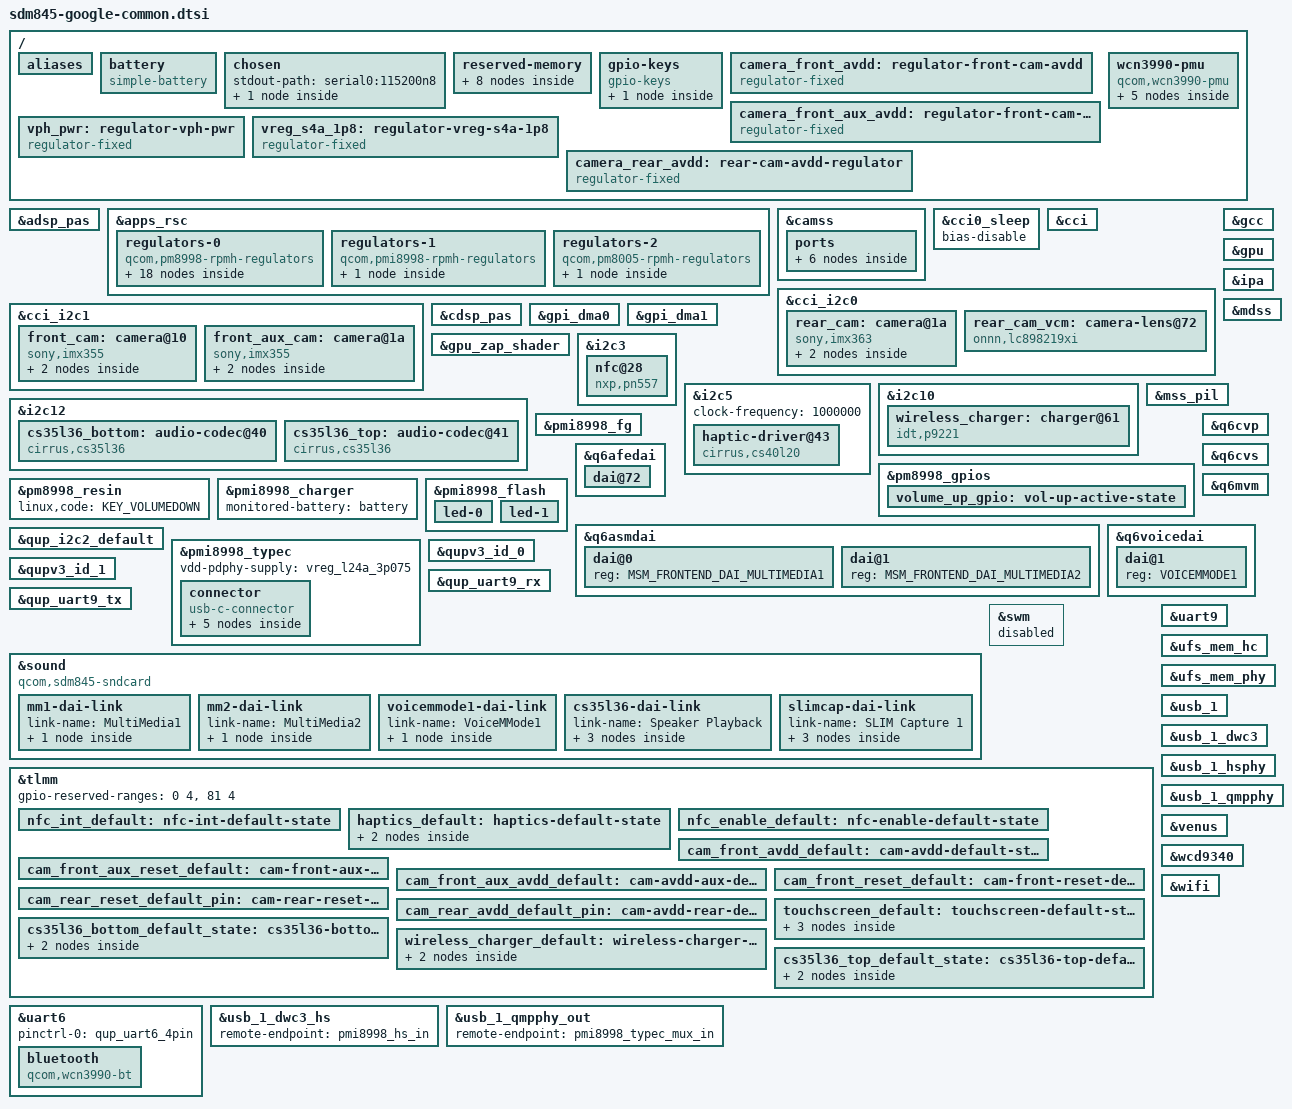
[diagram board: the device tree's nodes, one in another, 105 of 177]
// SPDX-License-Identifier: GPL-2.0-only

/dts-v1/;

#include <dt-bindings/arm/qcom,ids.h>
#include <dt-bindings/dma/qcom-gpi.h>
#include <dt-bindings/input/linux-event-codes.h>
#include <dt-bindings/interrupt-controller/irq.h>
#include <dt-bindings/leds/common.h>
#include <dt-bindings/media/video-interface-devices.h>
#include <dt-bindings/media/video-interfaces.h>
#include <dt-bindings/regulator/qcom,rpmh-regulator.h>
#include <dt-bindings/sound/qcom,q6afe.h>
#include <dt-bindings/sound/qcom,q6asm.h>
#include <dt-bindings/sound/qcom,q6voice.h>
#include <dt-bindings/sound/qcom,wcd934x.h>
#include <dt-bindings/usb/pd.h>

#include "sdm845.dtsi"
#include "sdm845-wcd9340.dtsi"
#include "pm8998.dtsi"
#include "pmi8998.dtsi"

/delete-node/ &mpss_region;
/delete-node/ &venus_mem;
/delete-node/ &cdsp_mem;
/delete-node/ &mba_region;
/delete-node/ &slpi_mem;
/delete-node/ &spss_mem;
/delete-node/ &rmtfs_mem;

/ {
	chassis-type = "handset";
	qcom,board-id = <0x00021505 0>;
	qcom,msm-id = <QCOM_ID_SDM845 0x20001>;

	aliases {
		serial0 = &uart9;
		serial1 = &uart6;
	};

	battery: battery {
		compatible = "simple-battery";
	};

	chosen {
		#address-cells = <2>;
		#size-cells = <2>;
		ranges;

		stdout-path = "serial0:115200n8";

		/* Use display framebuffer as setup by bootloader */
		framebuffer0: framebuffer-0 {
			compatible = "simple-framebuffer";
			memory-region = <&cont_splash_mem>;

			format = "a8r8g8b8";
		};
	};

	reserved-memory {
		cont_splash_mem: splash@9d400000 {
			reg = <0 0x9d400000 0 0x02400000>;
			no-map;
		};

		mpss_region: memory@8e000000 {
			reg = <0 0x8e000000 0 0x9800000>;
			no-map;
		};

		venus_mem: venus@97800000 {
			reg = <0 0x97800000 0 0x500000>;
			no-map;
		};

		cdsp_mem: cdsp-mem@97d00000 {
			reg = <0 0x97d00000 0 0x800000>;
			no-map;
		};

		mba_region: mba@98500000 {
			reg = <0 0x98500000 0 0x200000>;
			no-map;
		};

		slpi_mem: slpi@98700000 {
			reg = <0 0x98700000 0 0x1400000>;
			no-map;
		};

		spss_mem: spss@99b00000 {
			reg = <0 0x99b00000 0 0x100000>;
			no-map;
		};

		rmtfs_mem: rmtfs-region@f2700000 {
			compatible = "qcom,rmtfs-mem";
			reg = <0 0xf2700000 0 0x202000>;
			qcom,use-guard-pages;
			no-map;

			qcom,client-id = <1>;
			qcom,vmid = <QCOM_SCM_VMID_MSS_MSA>;
		};
	};

	gpio-keys {
		compatible = "gpio-keys";
		label = "Volume keys";
		autorepeat;

		pinctrl-0 = <&volume_up_gpio>;
		pinctrl-names = "default";

		key-vol-up {
			label = "Volume Up";
			linux,code = <KEY_VOLUMEUP>;
			gpios = <&pm8998_gpios 6 GPIO_ACTIVE_LOW>;
			debounce-interval = <15>;
		};
	};

	camera_front_avdd: regulator-front-cam-avdd {
		compatible = "regulator-fixed";
		regulator-name = "front_cam_avdd";

		regulator-min-microvolt = <2800000>;
		regulator-max-microvolt = <2800000>;

		gpios = <&tlmm 8 GPIO_ACTIVE_HIGH>;
		enable-active-high;

		pinctrl-0 = <&cam_front_avdd_default>;
		pinctrl-names = "default";

		vin-supply = <&vreg_bob>;
	};

	camera_front_aux_avdd: regulator-front-cam-aux-avdd {
		compatible = "regulator-fixed";
		regulator-name = "front_cam_aux_avdd";

		regulator-min-microvolt = <2800000>;
		regulator-max-microvolt = <2800000>;

		gpios = <&tlmm 14 GPIO_ACTIVE_HIGH>;
		enable-active-high;

		pinctrl-0 = <&cam_front_aux_avdd_default>;
		pinctrl-names = "default";

		vin-supply = <&vreg_bob>;
	};

	vph_pwr: regulator-vph-pwr {
		compatible = "regulator-fixed";
		regulator-name = "vph_pwr";
		regulator-min-microvolt = <3700000>;
		regulator-max-microvolt = <3700000>;
	};

	vreg_s4a_1p8: regulator-vreg-s4a-1p8 {
		compatible = "regulator-fixed";
		regulator-name = "vreg_s4a_1p8";

		regulator-min-microvolt = <1800000>;
		regulator-max-microvolt = <1800000>;
		regulator-always-on;
		regulator-boot-on;

		vin-supply = <&vph_pwr>;
	};

	/*
	 * CAM_VANA0 in the downstream overlay's cam-sensor@0: a GPIO switch off
	 * the BOB rail, same shape as the two front sensors' avdd above.
	 */
	camera_rear_avdd: rear-cam-avdd-regulator {
		compatible = "regulator-fixed";
		regulator-name = "rear_cam_avdd";

		regulator-min-microvolt = <2800000>;
		regulator-max-microvolt = <2800000>;

		gpios = <&tlmm 16 GPIO_ACTIVE_HIGH>;
		enable-active-high;

		pinctrl-0 = <&cam_rear_avdd_default_pin>;
		pinctrl-names = "default";

		vin-supply = <&vreg_bob>;
	};

	wcn3990-pmu {
		compatible = "qcom,wcn3990-pmu";

		vddio-supply = <&vreg_s4a_1p8>;
		vddxo-supply = <&vreg_l7a_1p8>;
		vddrf-supply = <&vreg_l17a_1p3>;
		vddch0-supply = <&vreg_l25a_3p3>;

		regulators {
			vreg_pmu_io: ldo0 {
				regulator-name = "vreg_pmu_io";
			};

			vreg_pmu_xo: ldo1 {
				regulator-name = "vreg_pmu_xo";
			};

			vreg_pmu_rf: ldo2 {
				regulator-name = "vreg_pmu_rf";
			};

			vreg_pmu_ch0: ldo3 {
				regulator-name = "vreg_pmu_ch0";
			};
		};
	};
};

&adsp_pas {
	firmware-name = "qcom/sdm845/Google/blueline/adsp.mbn";

	status = "okay";
};

&apps_rsc {
	regulators-0 {
		compatible = "qcom,pm8998-rpmh-regulators";
		qcom,pmic-id = "a";

		vdd-s1-supply = <&vph_pwr>;
		vdd-s2-supply = <&vph_pwr>;
		vdd-s3-supply = <&vph_pwr>;
		vdd-s4-supply = <&vph_pwr>;
		vdd-s5-supply = <&vph_pwr>;
		vdd-s6-supply = <&vph_pwr>;
		vdd-s7-supply = <&vph_pwr>;
		vdd-s8-supply = <&vph_pwr>;
		vdd-s9-supply = <&vph_pwr>;
		vdd-s10-supply = <&vph_pwr>;
		vdd-s11-supply = <&vph_pwr>;
		vdd-s12-supply = <&vph_pwr>;
		vdd-s13-supply = <&vph_pwr>;
		vdd-l1-l27-supply = <&vreg_s7a_1p025>;
		vdd-l2-l8-l17-supply = <&vreg_s3a_1p35>;
		vdd-l3-l11-supply = <&vreg_s7a_1p025>;
		vdd-l4-l5-supply = <&vreg_s7a_1p025>;
		vdd-l6-supply = <&vph_pwr>;
		vdd-l7-l12-l14-l15-supply = <&vreg_s5a_2p04>;
		vdd-l9-supply = <&vreg_bob>;
		vdd-l10-l23-l25-supply = <&vreg_bob>;
		vdd-l13-l19-l21-supply = <&vreg_bob>;
		vdd-l16-l28-supply = <&vreg_bob>;
		vdd-l18-l22-supply = <&vreg_bob>;
		vdd-l20-l24-supply = <&vreg_bob>;
		vdd-l26-supply = <&vreg_s3a_1p35>;
		vin-lvs-1-2-supply = <&vreg_s4a_1p8>;

		vreg_s3a_1p35: smps3 {
			regulator-min-microvolt = <1352000>;
			regulator-max-microvolt = <1352000>;
		};

		vreg_s5a_2p04: smps5 {
			regulator-min-microvolt = <1904000>;
			regulator-max-microvolt = <2040000>;
		};

		vreg_s7a_1p025: smps7 {
			regulator-min-microvolt = <900000>;
			regulator-max-microvolt = <1028000>;
		};

		vdda_mipi_dsi0_pll:
		vreg_l1a_0p875: ldo1 {
			regulator-min-microvolt = <880000>;
			regulator-max-microvolt = <880000>;
			regulator-initial-mode = <RPMH_REGULATOR_MODE_HPM>;
			regulator-boot-on;
		};

		vreg_l5a_0p8: ldo5 {
			regulator-min-microvolt = <800000>;
			regulator-max-microvolt = <800000>;
			regulator-initial-mode = <RPMH_REGULATOR_MODE_HPM>;
		};

		vreg_l12a_1p8: ldo12 {
			regulator-min-microvolt = <1800000>;
			regulator-max-microvolt = <1800000>;
			regulator-initial-mode = <RPMH_REGULATOR_MODE_HPM>;
		};

		vreg_l7a_1p8: ldo7 {
			regulator-min-microvolt = <1800000>;
			regulator-max-microvolt = <1800000>;
			regulator-initial-mode = <RPMH_REGULATOR_MODE_HPM>;
		};

		vreg_l13a_2p95: ldo13 {
			regulator-min-microvolt = <1800000>;
			regulator-max-microvolt = <2960000>;
			regulator-initial-mode = <RPMH_REGULATOR_MODE_HPM>;
		};

		vreg_l14a_1p8: ldo14 {
			regulator-min-microvolt = <1800000>;
			regulator-max-microvolt = <1800000>;
			regulator-initial-mode = <RPMH_REGULATOR_MODE_HPM>;
			regulator-boot-on;
			/*
			 * We can't properly bring the panel back if it gets turned off
			 * so keep it's regulators always on for now.
			 */
			regulator-always-on;
		};

		vreg_l17a_1p3: ldo17 {
			regulator-min-microvolt = <1304000>;
			regulator-max-microvolt = <1304000>;
			regulator-initial-mode = <RPMH_REGULATOR_MODE_HPM>;
		};

		vreg_l19a_3p3: ldo19 {
			regulator-min-microvolt = <3300000>;
			regulator-max-microvolt = <3312000>;
			regulator-initial-mode = <RPMH_REGULATOR_MODE_HPM>;
			/*
			 * The touchscreen needs this to be 3.3v, which is apparently
			 * quite close to the hardware limit for this LDO (3.312v)
			 * It must be kept in high power mode to prevent TS brownouts
			 */
			regulator-allowed-modes = <RPMH_REGULATOR_MODE_HPM>;
		};

		vreg_l20a_2p95: ldo20 {
			regulator-min-microvolt = <2960000>;
			regulator-max-microvolt = <2968000>;
			regulator-initial-mode = <RPMH_REGULATOR_MODE_HPM>;
		};

		vreg_l21a_2p95: ldo21 {
			regulator-min-microvolt = <2960000>;
			regulator-max-microvolt = <2968000>;
			regulator-initial-mode = <RPMH_REGULATOR_MODE_HPM>;
		};

		vreg_l24a_3p075: ldo24 {
			regulator-min-microvolt = <3088000>;
			regulator-max-microvolt = <3088000>;
			regulator-initial-mode = <RPMH_REGULATOR_MODE_HPM>;
		};

		vreg_l25a_3p3: ldo25 {
			regulator-min-microvolt = <3300000>;
			regulator-max-microvolt = <3312000>;
			regulator-initial-mode = <RPMH_REGULATOR_MODE_HPM>;
		};

		vdda_mipi_dsi0_1p2:
		vreg_l26a_1p2: ldo26 {
			regulator-min-microvolt = <1200000>;
			regulator-max-microvolt = <1200000>;
			regulator-initial-mode = <RPMH_REGULATOR_MODE_HPM>;
			regulator-boot-on;
		};

		vreg_l28a_3p0: ldo28 {
			regulator-min-microvolt = <2856000>;
			regulator-max-microvolt = <3008000>;
			regulator-initial-mode = <RPMH_REGULATOR_MODE_LPM>;
			regulator-boot-on;
			/*
			 * We can't properly bring the panel back if it gets turned off
			 * so keep it's regulators always on for now.
			 */
			regulator-always-on;
		};

		vreg_lvs1_1p8: lvs1 {
			regulator-min-microvolt = <1800000>;
			regulator-max-microvolt = <1800000>;
			/*
			 * Camera I/O rail. The IMX363 and the VD6281 colour sensor
			 * share CCI0 with the VCM and clamp the bus when this rail
			 * is off, so keep it on until the bus users are sequenced.
			 */
			regulator-always-on;
		};
	};

	regulators-1 {
		compatible = "qcom,pmi8998-rpmh-regulators";
		qcom,pmic-id = "b";

		vdd-bob-supply = <&vph_pwr>;

		vreg_bob: bob {
			regulator-min-microvolt = <3312000>;
			regulator-max-microvolt = <3600000>;
			regulator-initial-mode = <RPMH_REGULATOR_MODE_AUTO>;
			regulator-allow-bypass;
		};
	};

	regulators-2 {
		compatible = "qcom,pm8005-rpmh-regulators";
		qcom,pmic-id = "c";

		vdd-s1-supply = <&vph_pwr>;
		vdd-s2-supply = <&vph_pwr>;
		vdd-s3-supply = <&vph_pwr>;
		vdd-s4-supply = <&vph_pwr>;

		vreg_s3c_0p6: smps3 {
			regulator-min-microvolt = <600000>;
			regulator-max-microvolt = <600000>;
		};
	};
};

&camss {
	vdda-phy-supply = <&vreg_l1a_0p875>;
	vdda-pll-supply = <&vreg_l26a_1p2>;

	/*
	 * MCLK2 (GPIO15) is shared between both front camera sensors.
	 * The clock is generated by CAMCC, therefore the pin is
	 * configured here rather than in individual sensor nodes.
	 */
	pinctrl-0 = <&cam_mclk2_default>;
	pinctrl-1 = <&cam_mclk2_sleep>;
	pinctrl-names = "default", "sleep";

	status = "okay";

	ports {
		#address-cells = <1>;
		#size-cells = <0>;

		port@0 {
			reg = <0>;

			camss_endpoint0: endpoint {
				bus-type = <MEDIA_BUS_TYPE_CSI2_DPHY>;
				data-lanes = <0 1 2 3>;
				remote-endpoint = <&cam_rear_endpoint>;
			};
		};

		port@1 {
			reg = <1>;

			camss_endpoint1: endpoint {
				bus-type = <MEDIA_BUS_TYPE_CSI2_DPHY>;
				data-lanes = <0 1 2 3>;
				remote-endpoint = <&cam_aux_front_endpoint>;
			};
		};

		port@2 {
			reg = <2>;

			camss_endpoint2: endpoint {
				bus-type = <MEDIA_BUS_TYPE_CSI2_DPHY>;
				data-lanes = <0 1 2 3>;
				remote-endpoint = <&cam_front_endpoint>;
			};
		};
	};
};

&cci0_sleep {
	/* bus has external pull-up */
	/delete-property/ bias-pull-down;
	bias-disable;
};

&cci {
	status = "okay";
};

&cci_i2c0 {
	rear_cam: camera@1a {
		compatible = "sony,imx363";
		reg = <0x1a>;

		clocks = <&clock_camcc CAM_CC_MCLK0_CLK>;
		assigned-clocks = <&clock_camcc CAM_CC_MCLK0_CLK>;
		assigned-clock-rates = <24000000>;
		clock-frequency = <24000000>;

		reset-gpios = <&tlmm 80 GPIO_ACTIVE_LOW>;

		vana-supply = <&camera_rear_avdd>;
		vdig-supply = <&vreg_s3a_1p35>;
		vif-supply = <&vreg_lvs1_1p8>;

		pinctrl-0 = <&cam_rear_reset_default_pin &cam_mclk0_default>;
		pinctrl-names = "default";

		rotation = <90>;
		orientation = <MEDIA_ORIENTATION_BACK>;

		lens-focus = <&rear_cam_vcm>;

		port {
			cam_rear_endpoint: endpoint {
				data-lanes = <1 2 3 4>;
				link-frequencies = /bits/ 64 <636000000>;
				remote-endpoint = <&camss_endpoint0>;
			};
		};
	};

	/* OIS controller (Onsemi LC898123F40) @3e, VCM EEPROM @73 */

	rear_cam_vcm: camera-lens@72 {
		compatible = "onnn,lc898219xi";
		reg = <0x72>;

		vdd-supply = <&camera_rear_avdd>;
	};
};

&cci_i2c1 {
	/* actuator @0c */

	front_cam: camera@10 {
		compatible = "sony,imx355";
		reg = <0x10>;

		clocks = <&clock_camcc CAM_CC_MCLK2_CLK>;
		assigned-clocks = <&clock_camcc CAM_CC_MCLK2_CLK>;
		assigned-clock-rates = <24000000>;

		reset-gpios = <&tlmm 21 GPIO_ACTIVE_LOW>;

		avdd-supply = <&camera_front_avdd>;
		dvdd-supply = <&vreg_s3a_1p35>;
		dovdd-supply = <&vreg_lvs1_1p8>;

		pinctrl-0 = <&cam_front_reset_default>;
		pinctrl-names = "default";

		rotation = <270>;
		orientation = <MEDIA_ORIENTATION_FRONT>;

		port {
			cam_front_endpoint: endpoint {
				data-lanes = <1 2 3 4>;
				link-frequencies = /bits/ 64 <360000000>;
				remote-endpoint = <&camss_endpoint2>;
			};
		};
	};

	front_aux_cam: camera@1a {
		compatible = "sony,imx355";
		reg = <0x1a>;

		clocks = <&clock_camcc CAM_CC_MCLK2_CLK>;
		assigned-clocks = <&clock_camcc CAM_CC_MCLK2_CLK>;
		assigned-clock-rates = <24000000>;

		reset-gpios = <&tlmm 9 GPIO_ACTIVE_LOW>;

		avdd-supply = <&camera_front_aux_avdd>;
		dvdd-supply = <&vreg_s3a_1p35>;
		dovdd-supply = <&vreg_lvs1_1p8>;

		pinctrl-0 = <&cam_front_aux_reset_default>;
		pinctrl-names = "default";

		rotation = <270>;
		orientation = <MEDIA_ORIENTATION_FRONT>;

		port {
			cam_aux_front_endpoint: endpoint {
				data-lanes = <1 2 3 4>;
				link-frequencies = /bits/ 64 <360000000>;
				remote-endpoint = <&camss_endpoint1>;
			};
		};
	};

	/* eeprom @50, at24 driver says 8K */
};

&cdsp_pas {
	firmware-name = "qcom/sdm845/Google/blueline/cdsp.mbn";

	status = "okay";
};

&gcc {
	protected-clocks = <GCC_QSPI_CORE_CLK>,
			   <GCC_QSPI_CORE_CLK_SRC>,
			   <GCC_QSPI_CNOC_PERIPH_AHB_CLK>;
};

&gpi_dma0 {
	status = "okay";
};

&gpi_dma1 {
	status = "okay";
};

&gpu {
	status = "okay";
};

&gpu_zap_shader {
	firmware-name = "qcom/sdm845/Google/blueline/a630_zap.mbn";
};

&i2c3 {
	status = "okay";

	nfc@28 {
		compatible = "nxp,pn557", "nxp,nxp-nci-i2c";
		reg = <0x28>;

		interrupts-extended = <&tlmm 63 IRQ_TYPE_EDGE_RISING>;

		enable-gpios = <&tlmm 25 GPIO_ACTIVE_HIGH>;
		firmware-gpios = <&tlmm 79 GPIO_ACTIVE_HIGH>;

		pinctrl-0 = <&nfc_int_default &nfc_enable_default>;
		pinctrl-names = "default";
	};
};

&i2c5 {
	clock-frequency = <1000000>;

	status = "okay";

	haptic-driver@43 {
		compatible = "cirrus,cs40l20";
		reg = <0x43>;

		interrupts-extended = <&tlmm 88 IRQ_TYPE_LEVEL_LOW>;

		reset-gpios = <&tlmm 87 GPIO_ACTIVE_LOW>;

		vdd-a-supply = <&vreg_s4a_1p8>;
		vdd-p-supply = <&vph_pwr>;

		cirrus,boost-ind-nanohenry = <1000>;
		cirrus,boost-cap-microfarad = <4>;
		cirrus,boost-peak-milliamp = <4500>;

		pinctrl-0 = <&haptics_default>;
		pinctrl-names = "default";
	};
};

&i2c10 {
	status = "okay";

	wireless_charger: charger@61 {
		compatible = "idt,p9221";
		reg = <0x61>;

		interrupts-extended = <&tlmm 124 IRQ_TYPE_LEVEL_LOW>,
				      <&tlmm 36 IRQ_TYPE_EDGE_BOTH>;
		interrupt-names = "int", "pg";

		enable-gpios = <&tlmm 122 GPIO_ACTIVE_LOW>;

		pinctrl-0 = <&wireless_charger_default>;
		pinctrl-names = "default";
	};
};

&i2c12 {
	status = "okay";

	cs35l36_bottom: audio-codec@40 {
		compatible = "cirrus,cs35l36";
		reg = <0x40>;
		reset-gpios = <&tlmm 112 GPIO_ACTIVE_HIGH>;
		#sound-dai-cells = <0>;
		sound-name-prefix = "Right"; /* Bottom */
		VA-supply = <&vreg_s4a_1p8>;
		interrupts-extended = <&tlmm 115 IRQ_TYPE_LEVEL_LOW>;

		pinctrl-0 = <&cs35l36_bottom_default_state>;
		pinctrl-names = "default";

		cirrus,boost-ind-nanohenry = <1000>;
		cirrus,boost-ctl-select = <1>;
		cirrus,boost-ctl-millivolt = <10000>;
		cirrus,boost-peak-milliamp = <3700>;
		cirrus,temp-warn-threshold = <1>;
		cirrus,multi-amp-mode;
		cirrus,irq-drive-select = <0>;
		cirrus,irq-gpio-select = <0>;
	};

	cs35l36_top: audio-codec@41 {
		compatible = "cirrus,cs35l36";
		reg = <0x41>;
		reset-gpios = <&tlmm 75 GPIO_ACTIVE_HIGH>;
		#sound-dai-cells = <0>;
		sound-name-prefix = "Left"; /* Top */
		VA-supply = <&vreg_s4a_1p8>;
		interrupts-extended = <&tlmm 40 IRQ_TYPE_LEVEL_LOW>;

		pinctrl-0 = <&cs35l36_top_default_state>;
		pinctrl-names = "default";

		cirrus,boost-ind-nanohenry = <1000>;
		cirrus,boost-ctl-select = <0x01>;
		cirrus,boost-ctl-millivolt = <10000>;
		cirrus,boost-peak-milliamp = <3700>;
		cirrus,temp-warn-threshold = <1>;
		cirrus,multi-amp-mode;
		cirrus,irq-drive-select = <0>;
		cirrus,irq-gpio-select = <0>;
	};
};

&ipa {
	firmware-name = "qcom/sdm845/Google/blueline/ipa_fws.mbn";
	memory-region = <&ipa_fw_mem>;

	status = "okay";
};

&mdss {
	status = "okay";
};

&mss_pil {
	firmware-name = "qcom/sdm845/Google/blueline/mba.mbn",
			"qcom/sdm845/Google/blueline/modem.mbn";

	status = "okay";
};

&pm8998_gpios {
	volume_up_gpio: vol-up-active-state {
		pins = "gpio6";
		function = "normal";
		input-enable;
		bias-pull-up;
		qcom,drive-strength = <0>;
	};
};

&pm8998_resin {
	linux,code = <KEY_VOLUMEDOWN>;

	status = "okay";
};

&pmi8998_charger {
	monitored-battery = <&battery>;

	status = "okay";
};

&pmi8998_fg {
	monitored-battery = <&battery>;
	power-supplies = <&pmi8998_charger>;

	status = "okay";
};

&pmi8998_flash {
	status = "okay";

	/* upper part of the flash module */
	led-0 {
		function = LED_FUNCTION_FLASH;
		color = <LED_COLOR_ID_WHITE>;
		led-sources = <1>;
		led-max-microamp = <500000>;
		flash-max-microamp = <1500000>;
		flash-max-timeout-us = <1280000>;
		function-enumerator = <0>;
	};

	/* lower part of the flash module */
	led-1 {
		function = LED_FUNCTION_FLASH;
		color = <LED_COLOR_ID_WHITE>;
		led-sources = <2>;
		led-max-microamp = <500000>;
		flash-max-microamp = <1500000>;
		flash-max-timeout-us = <1280000>;
		function-enumerator = <1>;
	};
};

&q6afedai {
	dai@72 {
		reg = <QUATERNARY_TDM_RX_0>;

		qcom,tdm-sync-mode = <0>;
		qcom,tdm-sync-src = <1>;
		qcom,tdm-data-out = <0>;
		qcom,tdm-invert-sync = <0>;
		qcom,tdm-data-delay = <1>;
		qcom,tdm-data-align = <0>;
	};
};

&q6asmdai {
	dai@0 {
		reg = <MSM_FRONTEND_DAI_MULTIMEDIA1>;
	};

	dai@1 {
		reg = <MSM_FRONTEND_DAI_MULTIMEDIA2>;
	};
};

&q6cvp {
	status = "okay";
};

&q6cvs {
	status = "okay";
};

&q6mvm {
	status = "okay";
};

&q6voicedai {
	dai@1 {
		reg = <VOICEMMODE1>;
	};
};

&qup_i2c2_default {
	drive-strength = <2>;
	bias-disable;
};

&pmi8998_typec {
	status = "okay";

	vdd-pdphy-supply = <&vreg_l24a_3p075>;

	connector {
		compatible = "usb-c-connector";

		/*
		 * Sink only for now, as the PMI8998 charger doesn't provide
		 * the VBUS output yet. Switch to the dual power role with
		 * source PDOs, try-power-role and vbus-supply once it is
		 * supported.
		 *
		 * Higher voltage sink PDOs will be added once the charger
		 * driver programs the allowed USBIN adapter voltage.
		 */
		power-role = "sink";
		data-role = "dual";
		self-powered;

		sink-pdos = <PDO_FIXED(5000, 3000,
				       PDO_FIXED_USB_COMM |
				       PDO_FIXED_DATA_SWAP)>;
		op-sink-microwatt = <7600000>;

		ports {
			#address-cells = <1>;
			#size-cells = <0>;

			port@0 {
				reg = <0>;
				pmi8998_hs_in: endpoint {
					remote-endpoint = <&usb_1_dwc3_hs>;
				};
			};

			port@1 {
				reg = <1>;
				pmi8998_typec_mux_in: endpoint {
					remote-endpoint = <&usb_1_qmpphy_out>;
				};
			};
		};
	};
};

&qupv3_id_0 {
	status = "okay";
};

&qupv3_id_1 {
	status = "okay";
};

&qup_uart9_rx {
	drive-strength = <2>;
	bias-pull-up;
};

&qup_uart9_tx {
	drive-strength = <2>;
	bias-disable;
};

&sound {
	compatible = "qcom,sdm845-sndcard";
	model = "Pixel 3";
	pinctrl-0 = <&quat_mi2s_active>, <&quat_mi2s_sd0_active>,
		    <&quat_mi2s_sd1_active>;
	pinctrl-names = "default";

	audio-routing = "DMIC0", "MCLK", /* Top mic */
			"DMIC0", "MIC BIAS1",
			"DMIC3", "MCLK", /* Top-edge mic */
			"DMIC3", "MIC BIAS3",
			"DMIC4", "MCLK", /* Bottom mic */
			"DMIC4", "MIC BIAS4";

	/* mm[0-9]-dai-link nodes must be positioned first regardless of sorting */
	mm1-dai-link {
		link-name = "MultiMedia1";

		cpu {
			sound-dai = <&q6asmdai MSM_FRONTEND_DAI_MULTIMEDIA1>;
		};
	};

	mm2-dai-link {
		link-name = "MultiMedia2";

		cpu {
			sound-dai = <&q6asmdai MSM_FRONTEND_DAI_MULTIMEDIA2>;
		};
	};

	voicemmode1-dai-link {
		link-name = "VoiceMMode1";

		cpu {
			sound-dai = <&q6voicedai VOICEMMODE1>;
		};
	};

	cs35l36-dai-link {
		link-name = "Speaker Playback";

		codec {
			sound-dai = <&cs35l36_bottom>, <&cs35l36_top>;
		};

		cpu {
			sound-dai = <&q6afedai QUATERNARY_TDM_RX_0>;
		};

		platform {
			sound-dai = <&q6routing>;
		};
	};

	slimcap-dai-link {
		link-name = "SLIM Capture 1";

		codec {
			sound-dai = <&wcd9340 AIF1_CAP>;
		};

		cpu {
			sound-dai = <&q6afedai SLIMBUS_0_TX>;
		};

		platform {
			sound-dai = <&q6routing>;
		};
	};
};

&swm {
	/*
	 * Nothing hangs off the codec's SoundWire bus on this board: the
	 * speakers are CS35L36 amplifiers on QUAT_TDM. With an empty bus the
	 * controller reports port mismatches and frame-generator timeouts on
	 * every boot.
	 */
	status = "disabled";
};

&tlmm {
	gpio-reserved-ranges = < 0 4>, /* SPI (Intel MNH Pixel Visual Core) */
			       <81 4>; /* SPI (most likely Fingerprint Cards FPC1075) */

	nfc_int_default: nfc-int-default-state {
		pins = "gpio63";
		function = "gpio";
		drive-strength = <2>;
		bias-pull-down;
	};

	haptics_default: haptics-default-state {
		reset-pins {
			pins = "gpio87";
			function = "gpio";
			drive-strength = <2>;
			bias-disable;
		};

		irq-pins {
			pins = "gpio88";
			function = "gpio";
			drive-strength = <2>;
			bias-pull-up;
		};
	};

	nfc_enable_default: nfc-enable-default-state {
		pins = "gpio25", "gpio79";
		function = "gpio";
		drive-strength = <2>;
		bias-pull-down;
	};

	cam_front_avdd_default: cam-avdd-default-state {
		pins = "gpio8";
		function = "gpio";
		drive-strength = <2>;
		bias-disable;
	};

	cam_front_aux_reset_default: cam-front-aux-reset-default-state {
		pins = "gpio9";
		function = "gpio";
		drive-strength = <2>;
		bias-disable;
	};

	cam_front_aux_avdd_default: cam-avdd-aux-default-state {
		pins = "gpio14";
		function = "gpio";
		drive-strength = <2>;
		bias-disable;
	};

	cam_front_reset_default: cam-front-reset-default-state {
		pins = "gpio21";
		function = "gpio";
		drive-strength = <2>;
		bias-disable;
	};

	cam_rear_reset_default_pin: cam-rear-reset-default-pins {
		pins = "gpio80";
		function = "gpio";
		drive-strength = <2>;
		bias-disable;
	};

	cam_rear_avdd_default_pin: cam-avdd-rear-default-pins {
		pins = "gpio16";
		function = "gpio";
		drive-strength = <2>;
		bias-disable;
	};

	touchscreen_default: touchscreen-default-state {
		reset-pins {
			pins = "gpio99";
			function = "gpio";
			drive-strength = <8>;
			bias-pull-up;
		};

		irq-pins {
			pins = "gpio125";
			function = "gpio";
			drive-strength = <2>;
			bias-disable;
		};

		switch-pins {
			pins = "gpio136";
			function = "gpio";
			drive-strength = <2>;
			bias-disable;
		};
	};

	cs35l36_bottom_default_state: cs35l36-bottom-default-state {
		reset-pins {
			pins = "gpio112";
			function = "gpio";
			drive-strength = <2>;
			bias-disable;
		};

		irq-pins {
			pins = "gpio115";
			function = "gpio";
			drive-strength = <2>;
			bias-pull-up;
		};
	};

	wireless_charger_default: wireless-charger-default-state {
		pg-pins {
			pins = "gpio36";
			function = "gpio";
			drive-strength = <2>;
			bias-pull-down;
		};

		int-pins {
			pins = "gpio124";
			function = "gpio";
			drive-strength = <2>;
			bias-pull-up;
		};
	};

	cs35l36_top_default_state: cs35l36-top-default-state {
		irq-pins {
			pins = "gpio40";
			function = "gpio";
			drive-strength = <2>;
			bias-pull-up;
		};

		reset-pins {
			pins = "gpio75";
			function = "gpio";
			drive-strength = <2>;
			bias-disable;
		};
	};
};

&uart6 {
	pinctrl-0 = <&qup_uart6_4pin>;

	status = "okay";

	bluetooth {
		compatible = "qcom,wcn3990-bt";

		vddio-supply = <&vreg_pmu_io>;
		vddxo-supply = <&vreg_pmu_xo>;
		vddrf-supply = <&vreg_pmu_rf>;
		vddch0-supply = <&vreg_pmu_ch0>;

		max-speed = <3200000>;
	};
};

&uart9 {
	status = "okay";
};

&ufs_mem_hc {
	reset-gpios = <&tlmm 150 GPIO_ACTIVE_LOW>;

	vcc-supply = <&vreg_l20a_2p95>;
	vcc-max-microamp = <800000>;

	status = "okay";
};

&ufs_mem_phy {
	vdda-phy-supply = <&vreg_l1a_0p875>;
	vdda-pll-supply = <&vreg_l26a_1p2>;

	status = "okay";
};

&usb_1 {
	status = "okay";
};

&usb_1_dwc3 {
	dr_mode = "otg";
	usb-role-switch;
};

&usb_1_dwc3_hs {
	remote-endpoint = <&pmi8998_hs_in>;
};

&usb_1_hsphy {
	vdd-supply = <&vreg_l1a_0p875>;
	vdda-pll-supply = <&vreg_l12a_1p8>;
	vdda-phy-dpdm-supply = <&vreg_l24a_3p075>;

	qcom,imp-res-offset-value = <8>;
	qcom,hstx-trim-value = <QUSB2_V2_HSTX_TRIM_21_6_MA>;
	qcom,preemphasis-level = <QUSB2_V2_PREEMPHASIS_5_PERCENT>;
	qcom,preemphasis-width = <QUSB2_V2_PREEMPHASIS_WIDTH_HALF_BIT>;

	status = "okay";
};

&usb_1_qmpphy {
	vdda-phy-supply = <&vreg_l1a_0p875>;
	vdda-pll-supply = <&vreg_l26a_1p2>;

	status = "okay";
};

&usb_1_qmpphy_out {
	remote-endpoint = <&pmi8998_typec_mux_in>;
};

&venus {
	firmware-name = "qcom/sdm845/Google/blueline/venus.mbn";

	status = "okay";
};

&wcd9340 {
	/* PM8998 LN_BB_CLK2 feeds the Pixel Visual Core on this board */
	clocks = <&rpmhcc RPMH_LN_BB_CLK3>;
	reset-gpios = <&tlmm 64 GPIO_ACTIVE_HIGH>;
	vdd-buck-supply = <&vreg_s4a_1p8>;
	vdd-buck-sido-supply = <&vreg_s4a_1p8>;
	vdd-tx-supply = <&vreg_s4a_1p8>;
	vdd-rx-supply = <&vreg_s4a_1p8>;
	vdd-io-supply = <&vreg_s4a_1p8>;
};

&wifi {
	vdd-0.8-cx-mx-supply = <&vreg_l5a_0p8>;
	vdd-1.8-xo-supply = <&vreg_pmu_xo>;
	vdd-1.3-rfa-supply = <&vreg_pmu_rf>;
	vdd-3.3-ch0-supply = <&vreg_pmu_ch0>;

	qcom,snoc-host-cap-8bit-quirk;

	status = "okay";
};
